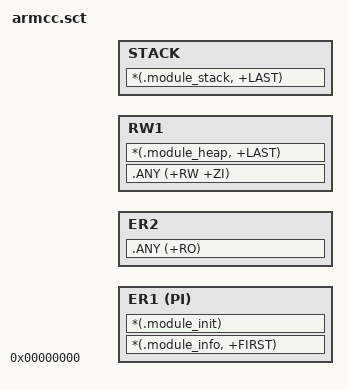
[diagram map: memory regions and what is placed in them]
LR_CODE 0 RELOC {
  ER1 0 PI {
    *(.module_info, +FIRST)
    *(.module_init)
  }
  ER2 +0 {
    .ANY (+RO)
  }
  RW1 +0 {
    .ANY (+RW +ZI)
    *(.module_heap, +LAST)
  }
  STACK +0 {
    *(.module_stack, +LAST)
  }
}
